# CW32L012 register map
Vendor: Wuhan Xinyuan Semiconductor Co.Ltd; Series: ARMCM0P; File version: 1.2
CPU: CM0+ r0p1, little endian, no MPU, no FPU, 2 interrupt priority bits
Registers are 32-bit, read-write, no defined reset value unless marked. A register's access mark holds for its fields unless they carry their own. Offsets are from the block's base; [hi:lo] are bit positions; {n}, {i} and the like mark numbered series.

## SPI1
Base 0x40000800
Same registers: SPI2 0x40000400, SPI3 0x40003400
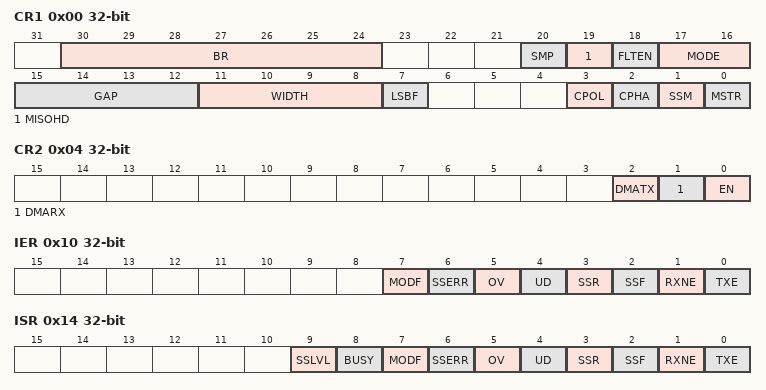
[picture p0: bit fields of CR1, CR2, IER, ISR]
0x00 CR1 — Control register1
  [30:24] BR, [20] SMP, [19] MISOHD, [18] FLTEN, [17:16] MODE, [15:12] GAP, [11:8] WIDTH, [7] LSBF, [3] CPOL, [2] CPHA, [1] SSM, [0] MSTR
0x04 CR2 — Control register2
  [2] DMATX, [1] DMARX, [0] EN
0x08 CR3
  [0] HDOE
0x0C SSI — Slave slect register
  [0] SSI
0x10 IER — Interrupt enable register
  [7] MODF, [6] SSERR, [5] OV, [4] UD, [3] SSR, [2] SSF, [1] RXNE, [0] TXE
0x14 ISR ro — Interrupt status register
  [9] SSLVL, [8] BUSY, [7] MODF, [6] SSERR, [5] OV, [4] UD, [3] SSR, [2] SSF, [1] RXNE, [0] TXE
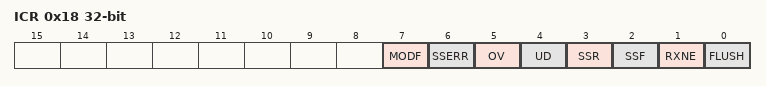
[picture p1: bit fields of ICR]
0x18 ICR — Interrupt flag clear register
  [7] MODF, [6] SSERR, [5] OV, [4] UD, [3] SSR, [2] SSF, [1] RXNE, [0] FLUSH
0x1C DR — Data register
  [15:0] DR

## SYSCTRL — System Ctrl
Base 0x40004000
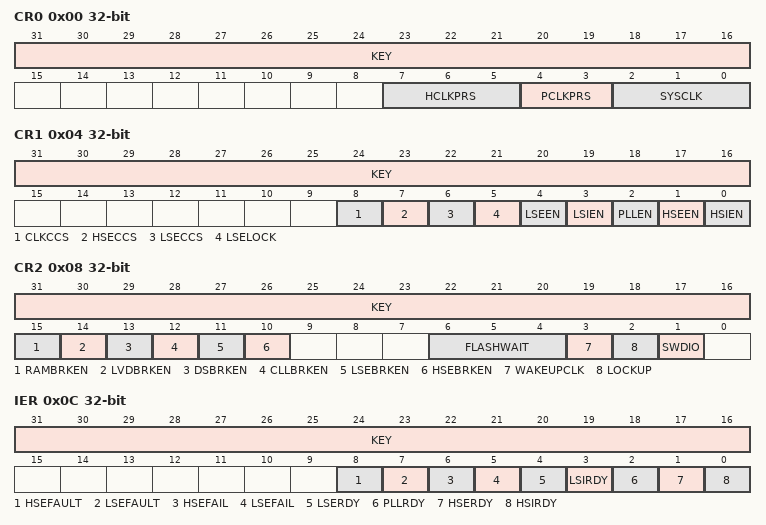
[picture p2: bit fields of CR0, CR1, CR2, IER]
0x00 CR0 — Control Reg0
  [31:16] KEY wo, [7:5] HCLKPRS, [4:3] PCLKPRS, [2:0] SYSCLK
0x04 CR1 — Control Reg1
  [31:16] KEY wo, [8] CLKCCS, [7] HSECCS, [6] LSECCS, [5] LSELOCK, [4] LSEEN, [3] LSIEN, [2] PLLEN, [1] HSEEN, [0] HSIEN
0x08 CR2 — Control Reg2
  [31:16] KEY wo, [15] RAMBRKEN, [14] LVDBRKEN, [13] DSBRKEN, [12] CLLBRKEN, [11] LSEBRKEN, [10] HSEBRKEN, [6:4] FLASHWAIT, [3] WAKEUPCLK, [2] LOCKUP, [1] SWDIO
0x0C IER — Interupt Enable Reg
  [31:16] KEY wo, [8] HSEFAULT, [7] LSEFAULT, [6] HSEFAIL, [5] LSEFAIL, [4] LSERDY, [3] LSIRDY, [2] PLLRDY, [1] HSERDY, [0] HSIRDY
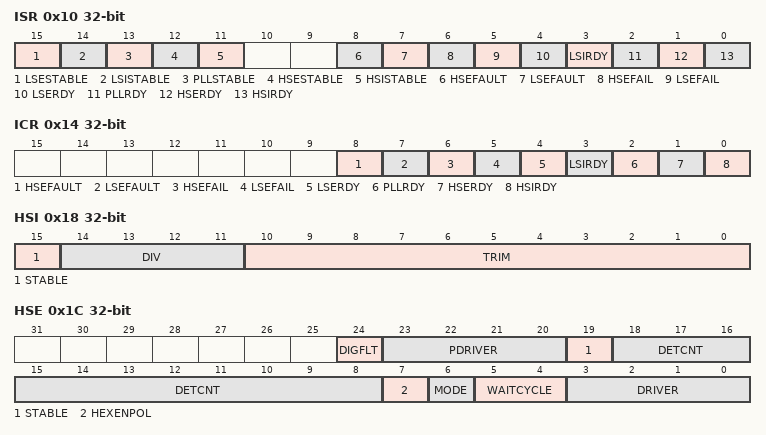
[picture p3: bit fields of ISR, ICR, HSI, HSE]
0x10 ISR ro — Interupt Status Reg
  [15] LSESTABLE, [14] LSISTABLE, [13] PLLSTABLE, [12] HSESTABLE, [11] HSISTABLE, [8] HSEFAULT, [7] LSEFAULT, [6] HSEFAIL, [5] LSEFAIL, [4] LSERDY, [3] LSIRDY, [2] PLLRDY, [1] HSERDY, [0] HSIRDY
0x14 ICR — Interupt Clear Reg
  [8] HSEFAULT, [7] LSEFAULT, [6] HSEFAIL, [5] LSEFAIL, [4] LSERDY, [3] LSIRDY, [2] PLLRDY, [1] HSERDY, [0] HSIRDY
0x18 HSI — HSI Control Reg
  [15] STABLE ro, [14:11] DIV, [10:0] TRIM
0x1C HSE
  [24] DIGFLT, [23:20] PDRIVER, [19] STABLE ro, [18:8] DETCNT, [7] HEXENPOL, [6] MODE, [5:4] WAITCYCLE, [3:0] DRIVER
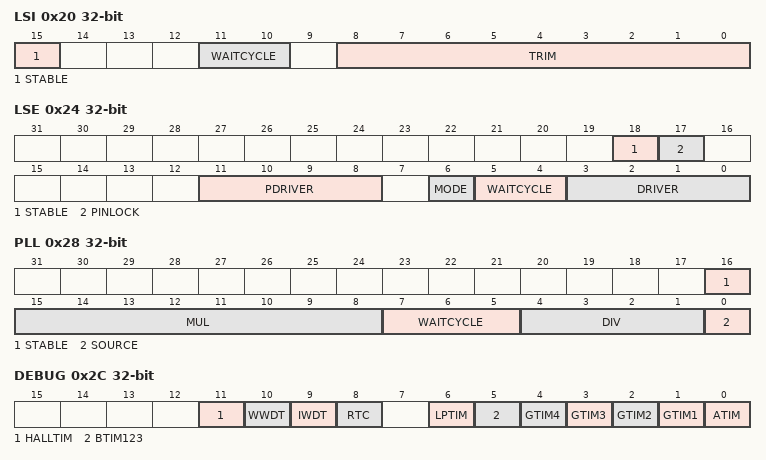
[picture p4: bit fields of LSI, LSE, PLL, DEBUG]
0x20 LSI — LSI Control Reg
  [15] STABLE ro, [11:10] WAITCYCLE, [8:0] TRIM
0x24 LSE — LSE Control Reg
  [18] STABLE ro, [17] PINLOCK, [11:8] PDRIVER, [6] MODE, [5:4] WAITCYCLE, [3:0] DRIVER
0x28 PLL — PLL Control Reg
  [16] STABLE ro, [15:8] MUL, [7:5] WAITCYCLE, [4:1] DIV, [0] SOURCE
0x2C DEBUG — Debug Control Reg
  [11] HALLTIM, [10] WWDT, [9] IWDT, [8] RTC, [6] LPTIM, [5] BTIM123, [n] GTIM{n} (n=1..4), [0] ATIM
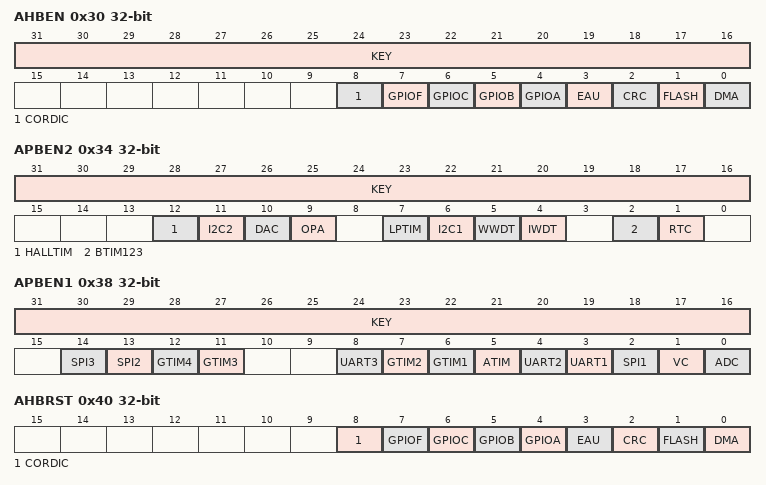
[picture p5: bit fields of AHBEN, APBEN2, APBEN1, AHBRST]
0x30 AHBEN — AHB Clock Control Reg
  [31:16] KEY wo, [8] CORDIC, [7] GPIOF, [6] GPIOC, [5] GPIOB, [4] GPIOA, [3] EAU, [2] CRC, [1] FLASH, [0] DMA
0x34 APBEN2 — APB Clock Control Reg2
  [31:16] KEY wo, [12] HALLTIM, [11] I2C2, [10] DAC, [9] OPA, [7] LPTIM, [6] I2C1, [5] WWDT, [4] IWDT, [2] BTIM123, [1] RTC
0x38 APBEN1 — APB Clock Control Reg1
  [31:16] KEY wo, [14] SPI3, [13] SPI2, [12] GTIM4, [11] GTIM3, [8] UART3, [7] GTIM2, [6] GTIM1, [5] ATIM, [4] UART2, [3] UART1, [2] SPI1, [1] VC, [0] ADC
0x40 AHBRST — AHB Reset Control Reg
  [8] CORDIC, [7] GPIOF, [6] GPIOC, [5] GPIOB, [4] GPIOA, [3] EAU, [2] CRC, [1] FLASH, [0] DMA
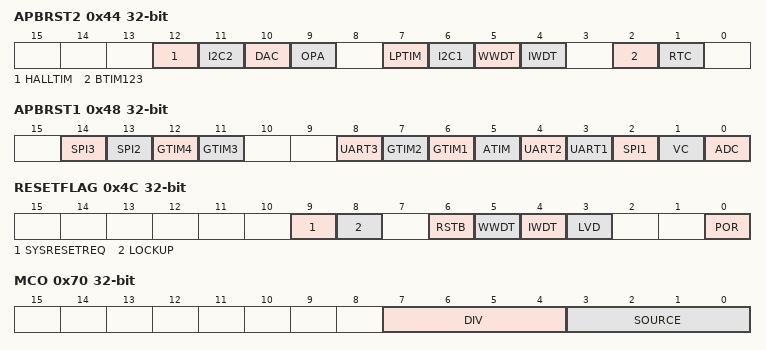
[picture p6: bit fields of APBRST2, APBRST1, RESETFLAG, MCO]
0x44 APBRST2 — APB Reset Control Reg2
  [12] HALLTIM, [11] I2C2, [10] DAC, [9] OPA, [7] LPTIM, [6] I2C1, [5] WWDT, [4] IWDT, [2] BTIM123, [1] RTC
0x48 APBRST1 — APB Reset Control Reg1
  [14] SPI3, [13] SPI2, [12] GTIM4, [11] GTIM3, [8] UART3, [7] GTIM2, [6] GTIM1, [5] ATIM, [4] UART2, [3] UART1, [2] SPI1, [1] VC, [0] ADC
0x4C RESETFLAG — Reset Status Reg
  [9] SYSRESETREQ, [8] LOCKUP, [6] RSTB, [5] WWDT, [4] IWDT, [3] LVD, [0] POR
0x70 MCO — Master Clock Output Control Reg
  [7:4] DIV, [3:0] SOURCE

## VC1
Base 0x40000084
Same registers: VC2 0x40000094, VC3 0x40000184, VC4 0x40000194
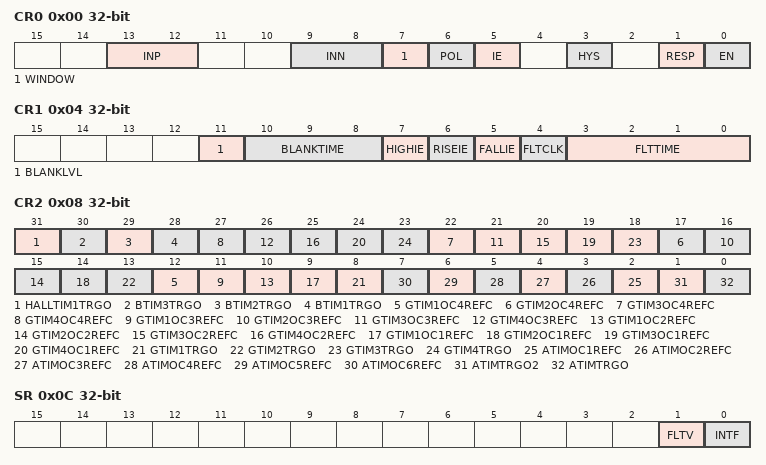
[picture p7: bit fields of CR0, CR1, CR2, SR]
0x00 CR0 — Control register0
  [13:12] INP, [9:8] INN, [7] WINDOW, [6] POL, [5] IE, [3] HYS, [1] RESP, [0] EN
0x04 CR1 — Control register1
  [11] BLANKLVL, [10:8] BLANKTIME, [7] HIGHIE, [6] RISEIE, [5] FALLIE, [4] FLTCLK, [3:0] FLTTIME
0x08 CR2 — Control register1
  [31] HALLTIM1TRGO, [30] BTIM3TRGO, [29] BTIM2TRGO, [28] BTIM1TRGO, [5n+7] GTIM{n}OC4REFC (n=1..4), [5n+6] GTIM{n}OC3REFC (n=1..4), [5n+5] GTIM{n}OC2REFC (n=1..4), [5n+4] GTIM{n}OC1REFC (n=1..4), [5n+3] GTIM{n}TRGO (n=1..4), [n+1] ATIMOC{n}REFC (n=1..6), [1] ATIMTRGO2, [0] ATIMTRGO
0x0C SR — Status register
  [1] FLTV ro, [0] INTF

## VC12REF
Base 0x40000080
Same registers: VC34REF 0x40000180
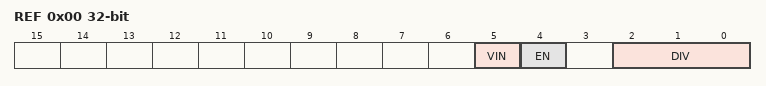
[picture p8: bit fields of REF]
0x00 REF — VCREF Control register
  [5] VIN, [4] EN, [2:0] DIV

## WWDT
Base 0x40005400
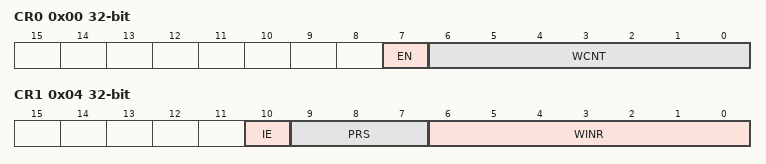
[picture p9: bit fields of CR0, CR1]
0x00 CR0 — Control register0
  [7] EN, [6:0] WCNT
0x04 CR1 — Control register1
  [10] IE
  [9:7] PRS — desc PRESCALE
  [6:0] WINR
0x08 SR — status register
  [0] POV
